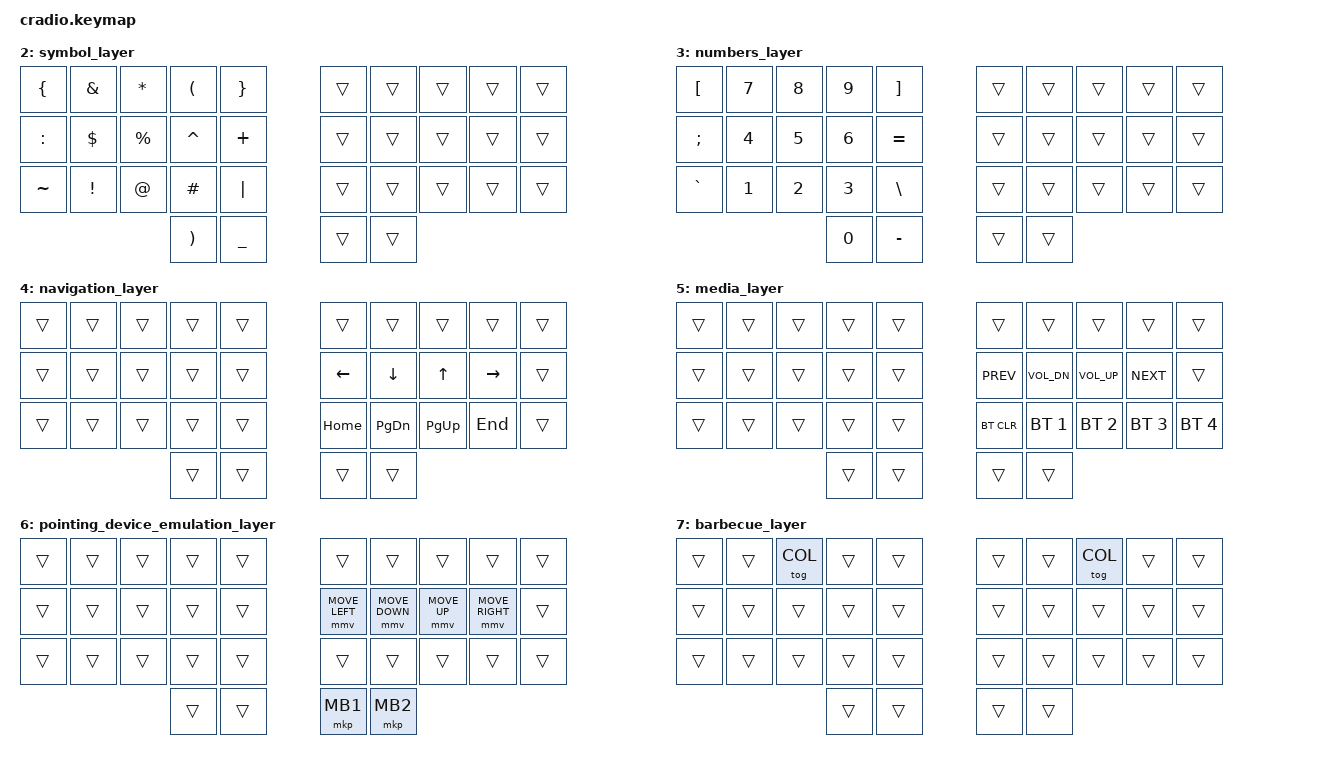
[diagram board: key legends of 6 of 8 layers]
// Copyright (c) 2022 The ZMK Contributors
// SPDX-License-Identifier: MIT

#include <behaviors.dtsi>
#include <dt-bindings/zmk/keys.h>
#include <dt-bindings/zmk/bt.h>
#include <dt-bindings/zmk/pointing.h>


// Home row mods macro
#define HRML(k1,k2,k3,k4) &ht LGUI k1  &ht LALT k2  &ht LCTRL k3  &ht LSHIFT k4
#define HRMR(k1,k2,k3,k4) &ht RSHIFT k1  &ht RCTRL k2  &ht LALT k3  &ht RGUI k4
#define RAM(k) &ht RALT k

#define BAS 0
#define COL 1
#define SYM 2
#define NUM 3
#define NAV 4
#define MED 5
#define PDE 6
#define BBQ 7

#define BT_1 &bt BT_SEL 1
#define BT_2 &bt BT_SEL 2
#define BT_3 &bt BT_SEL 3
#define BT_4 &bt BT_SEL 4

#define MNEXT &kp C_NEXT
#define MPREV &kp C_PREV
#define MVOLU &kp C_VOL_UP
#define MVOLD &kp C_VOL_DN

#define PDE_L &mmv MOVE_LEFT
#define PDE_R &mmv MOVE_RIGHT
#define PDE_U &mmv MOVE_UP
#define PDE_D &mmv MOVE_DOWN

/ {
    combos {
        compatible = "zmk,combos";
        combo_tab {
            timeout-ms = <100>;
            key-positions = <31 32>;
            bindings = <&kp TAB>;
        };
        combo_del {
            timeout-ms = <100>;
            key-positions = <32 33>;
            bindings = <&kp DEL>;
        };
    };
};


/ {
    behaviors {
        ht: hold_tap {
            compatible = "zmk,behavior-hold-tap";
            #binding-cells = <2>;
            flavor = "tap-preferred";
            tapping-term-ms = <220>;
            quick-tap-ms = <150>;
            require-prior-idle-ms = <125>;
            bindings = <&kp>, <&kp>;
        };
    };

    conditional_layers {
        compatible = "zmk,conditional-layers";
        bbq_layer {
            if-layers = <MED NUM>;
            then-layer = <BBQ>;
        };
        pde_layer {
            if-layers = <MED NAV>;
            then-layer = <PDE>;
        };
    };

    keymap {
        compatible = "zmk,keymap";
        default_layer { // Layer 0 - BAS
            bindings = <
        //╭──────────┬──────────┬──────────┬──────────┬──────────╮   ╭──────────┬──────────┬──────────┬──────────┬──────────╮
            &kp Q      &kp W      &kp E      &kp R      &kp T          &kp Y      &kp U      &kp I      &kp O      &kp P
        //├──────────┼──────────┼──────────┼──────────┼──────────┤   ├──────────┼──────────┼──────────┼──────────┼──────────┤
            HRML(A,        S,         D,         F)     &kp G          &kp H      HRMR(J,        K,         L,        SQT)
        //├──────────┼──────────┼──────────┼──────────┼──────────┤   ├──────────┼──────────┼──────────┼──────────┼──────────┤
            &kp Z      RAM(X)     &kp C      &kp V      &kp B          &kp N      &kp M      &kp COMMA  RAM(DOT)   &kp FSLH
        //╰──────────┴──────────┴──────────┼──────────┼──────────┤   ├──────────┼──────────┼──────────┴──────────┴──────────╯
                                        &lt MED ESC   &lt NAV SPACE  &lt SYM ENTER &lt NUM BSPC
        //                                 ╰──────────┴──────────╯   ╰──────────┴──────────╯
            >;
        };

        colemak_layer { // Layer 1 - COL
            bindings = <
        //╭──────────┬──────────┬──────────┬──────────┬──────────╮   ╭──────────┬──────────┬──────────┬──────────┬──────────╮
            &kp Q      &kp W      &kp F      &kp P      &kp B          &kp J      &kp L      &kp U      &kp Y      &kp SQT
        //├──────────┼──────────┼──────────┼──────────┼──────────┤   ├──────────┼──────────┼──────────┼──────────┼──────────┤
            HRML(A,        R,         S,         T)     &kp G          &kp M      HRMR(N,        E,         I,        O)
        //├──────────┼──────────┼──────────┼──────────┼──────────┤   ├──────────┼──────────┼──────────┼──────────┼──────────┤
            &kp Z      RAM(X)     &kp C      &kp D      &kp V          &kp K      &kp H      &kp COMMA  RAM(DOT)   &kp FSLH
        //╰──────────┴──────────┴──────────┼──────────┼──────────┤   ├──────────┼──────────┼──────────┴──────────┴──────────╯
                                             &trans     &trans         &trans     &trans
        //                                 ╰──────────┴──────────╯   ╰──────────┴──────────╯
            >;
        };

        symbol_layer { // Layer 2 - SYM
            bindings = <
        //╭──────────┬──────────┬──────────┬──────────┬──────────╮   ╭──────────┬──────────┬──────────┬──────────┬──────────╮
            &kp LBRC   &kp AMPS   &kp ASTRK  &kp LPAR   &kp RBRC       &trans     &trans     &trans     &trans     &trans
        //├──────────┼──────────┼──────────┼──────────┼──────────┤   ├──────────┼──────────┼──────────┼──────────┼──────────┤
            &kp COLON  &kp DLLR   &kp PRCNT  &kp CARET  &kp PLUS       &trans     &trans     &trans     &trans     &trans
        //├──────────┼──────────┼──────────┼──────────┼──────────┤   ├──────────┼──────────┼──────────┼──────────┼──────────┤
            &kp TILDE  &kp EXCL   &kp AT     &kp HASH   &kp PIPE       &trans     &trans     &trans     &trans     &trans
        //╰──────────┴──────────┴──────────┼──────────┼──────────┤   ├──────────┼──────────┼──────────┴──────────┴──────────╯
                                             &kp RPAR   &kp UNDER      &trans     &trans
        //                                 ╰──────────┴──────────╯   ╰──────────┴──────────╯
            >;
        };

        numbers_layer { // Layer 3 - NUM
            bindings = <
        //╭──────────┬──────────┬──────────┬──────────┬──────────╮   ╭──────────┬──────────┬──────────┬──────────┬──────────╮
            &kp LBKT   &kp N7     &kp N8     &kp N9     &kp RBKT       &trans     &trans     &trans     &trans     &trans
        //├──────────┼──────────┼──────────┼──────────┼──────────┤   ├──────────┼──────────┼──────────┼──────────┼──────────┤
            &kp SEMI   &kp N4     &kp N5     &kp N6     &kp EQUAL      &trans     &trans     &trans     &trans     &trans
        //├──────────┼──────────┼──────────┼──────────┼──────────┤   ├──────────┼──────────┼──────────┼──────────┼──────────┤
            &kp GRAVE  &kp N1     &kp N2     &kp N3     &kp BSLH       &trans     &trans     &trans     &trans     &trans
        //╰──────────┴──────────┴──────────┼──────────┼──────────┤   ├──────────┼──────────┼──────────┴──────────┴──────────╯
                                             &kp N0     &kp MINUS      &trans     &trans
        //                                 ╰──────────┴──────────╯   ╰──────────┴──────────╯
            >;
        };

        navigation_layer { // Layer 4 - NAV
            bindings = <
        //╭──────────┬──────────┬──────────┬──────────┬──────────╮   ╭──────────┬──────────┬──────────┬──────────┬──────────╮
            &trans     &trans     &trans     &trans     &trans         &trans     &trans     &trans     &trans     &trans
        //├──────────┼──────────┼──────────┼──────────┼──────────┤   ├──────────┼──────────┼──────────┼──────────┼──────────┤
            &trans     &trans     &trans     &trans     &trans         &kp LEFT   &kp DOWN   &kp UP     &kp RIGHT  &trans
        //├──────────┼──────────┼──────────┼──────────┼──────────┤   ├──────────┼──────────┼──────────┼──────────┼──────────┤
            &trans     &trans     &trans     &trans     &trans         &kp HOME   &kp PG_DN  &kp PG_UP  &kp END    &trans
        //╰──────────┴──────────┴──────────┼──────────┼──────────┤   ├──────────┼──────────┼──────────┴──────────┴──────────╯
                                             &trans     &trans         &trans     &trans
        //                                 ╰──────────┴──────────╯   ╰──────────┴──────────╯
            >;
        };




        media_layer { // Layer 5 - MED
            bindings = <
        //╭──────────┬──────────┬──────────┬──────────┬──────────╮   ╭──────────┬──────────┬──────────┬──────────┬──────────╮
            &trans     &trans     &trans     &trans     &trans         &trans     &trans     &trans     &trans     &trans
        //├──────────┼──────────┼──────────┼──────────┼──────────┤   ├──────────┼──────────┼──────────┼──────────┼──────────┤
            &trans     &trans     &trans     &trans     &trans         MPREV      MVOLD      MVOLU      MNEXT      &trans
        //├──────────┼──────────┼──────────┼──────────┼──────────┤   ├──────────┼──────────┼──────────┼──────────┼──────────┤
            &trans     &trans     &trans     &trans     &trans         &bt BT_CLR BT_1       BT_2       BT_3       BT_4
        //╰──────────┴──────────┴──────────┼──────────┼──────────┤   ├──────────┼──────────┼──────────┴──────────┴──────────╯
                                             &trans     &trans         &trans     &trans
        //                                 ╰──────────┴──────────╯   ╰──────────┴──────────╯
            >;
        };

        pointing_device_emulation_layer { // Layer 6 - PDE
            bindings = <
        //╭──────────┬──────────┬──────────┬──────────┬──────────╮   ╭──────────┬──────────┬──────────┬──────────┬──────────╮
            &trans     &trans     &trans     &trans     &trans         &trans     &trans     &trans     &trans     &trans
        //├──────────┼──────────┼──────────┼──────────┼──────────┤   ├──────────┼──────────┼──────────┼──────────┼──────────┤
            &trans     &trans     &trans     &trans     &trans         PDE_L      PDE_D      PDE_U      PDE_R      &trans
        //├──────────┼──────────┼──────────┼──────────┼──────────┤   ├──────────┼──────────┼──────────┼──────────┼──────────┤
            &trans     &trans     &trans     &trans     &trans         &trans     &trans     &trans     &trans     &trans
        //╰──────────┴──────────┴──────────┼──────────┼──────────┤   ├──────────┼──────────┼──────────┴──────────┴──────────╯
                                             &trans     &trans         &mkp MB1   &mkp MB2
        //                                 ╰──────────┴──────────╯   ╰──────────┴──────────╯
            >;
        };

        barbecue_layer { // Layer 7 - BBQ
            bindings = <
        //╭──────────┬──────────┬──────────┬──────────┬──────────╮   ╭──────────┬──────────┬──────────┬──────────┬──────────╮
            &trans     &trans     &tog COL   &trans     &trans         &trans     &trans     &tog COL   &trans     &trans
        //├──────────┼──────────┼──────────┼──────────┼──────────┤   ├──────────┼──────────┼──────────┼──────────┼──────────┤
            &trans     &trans     &trans     &trans     &trans         &trans     &trans     &trans     &trans     &trans
        //├──────────┼──────────┼──────────┼──────────┼──────────┤   ├──────────┼──────────┼──────────┼──────────┼──────────┤
            &trans     &trans     &trans     &trans     &trans         &trans     &trans     &trans     &trans     &trans
        //╰──────────┴──────────┴──────────┼──────────┼──────────┤   ├──────────┼──────────┼──────────┴──────────┴──────────╯
                                             &trans     &trans         &trans     &trans
        //                                 ╰──────────┴──────────╯   ╰──────────┴──────────╯
            >;
        };

    };
};
